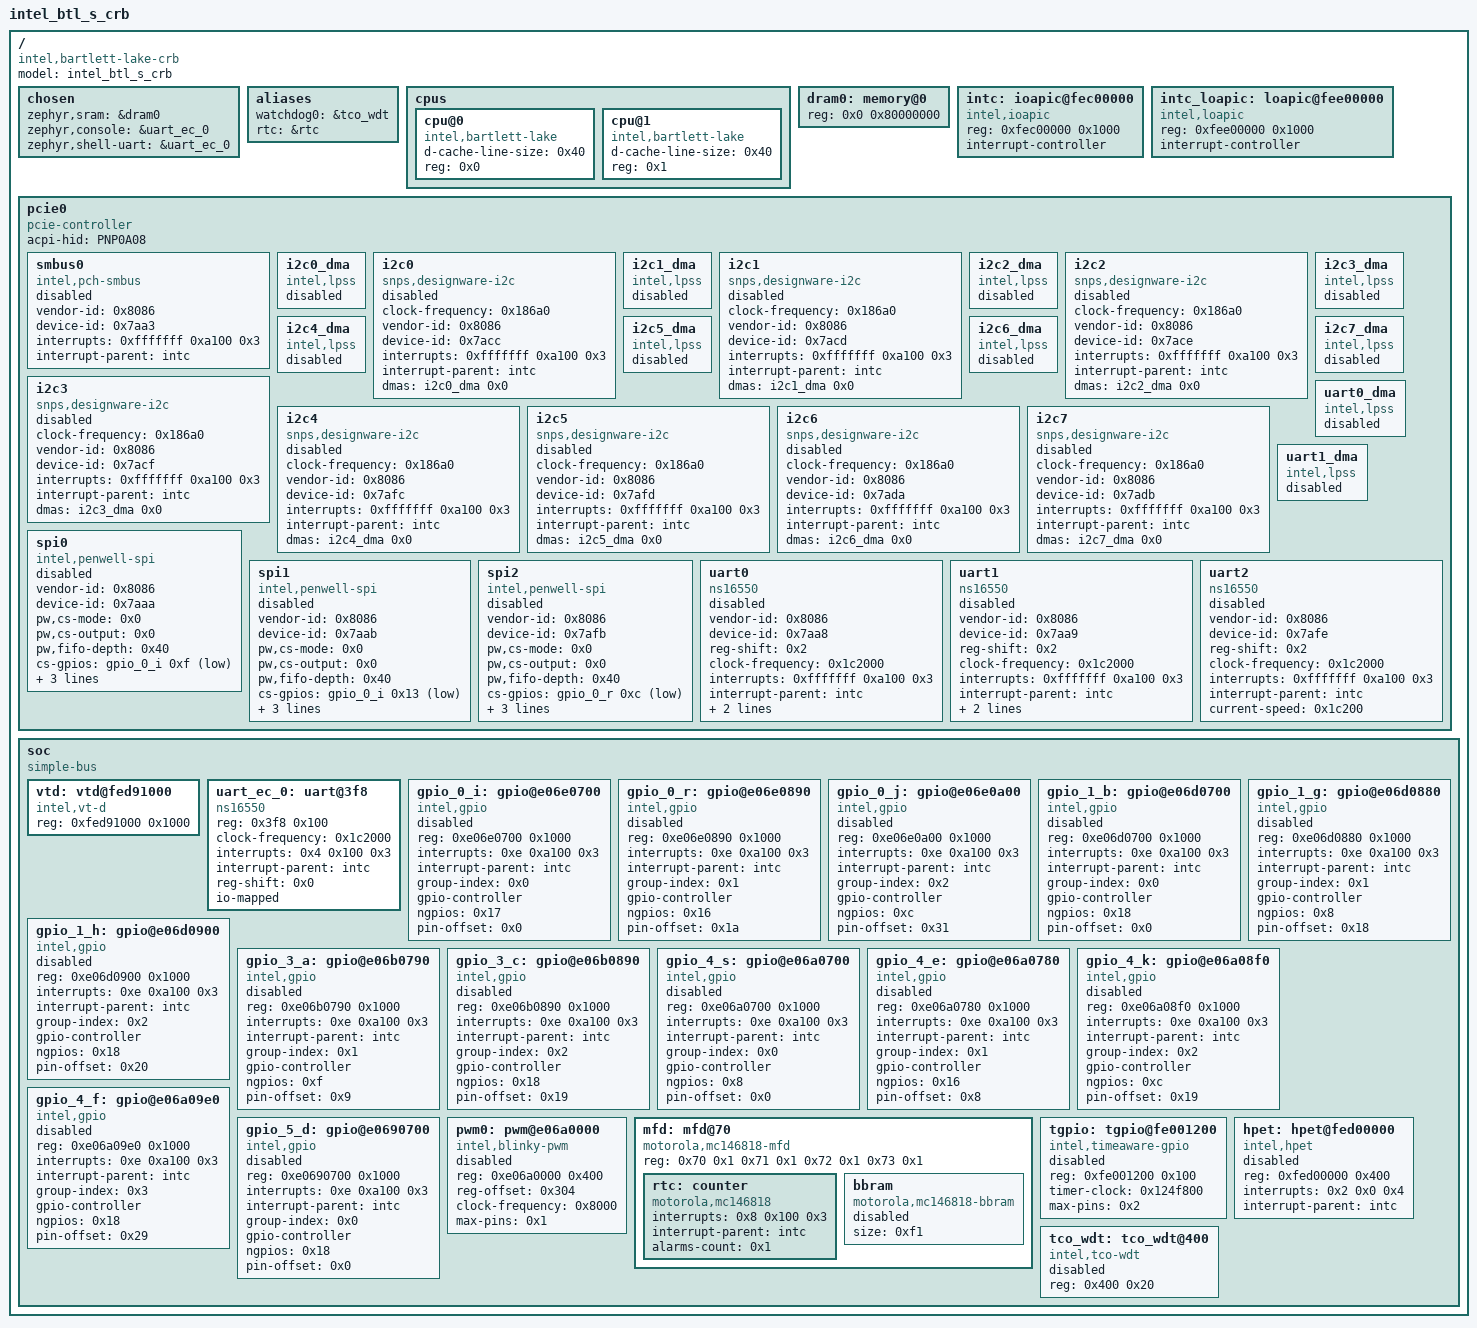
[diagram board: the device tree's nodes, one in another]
/dts-v1/;

/* node '/' defined in zephyr/dts/common/skeleton.dtsi:9 */
/ {
	#address-cells = < 0x1 >;               /* in zephyr/dts/common/skeleton.dtsi:10 */
	#size-cells = < 0x1 >;                  /* in zephyr/dts/common/skeleton.dtsi:11 */
	model = "intel_btl_s_crb";              /* in zephyr/boards/intel/btl/intel_btl_s_crb.dts:15 */
	compatible = "intel,bartlett-lake-crb"; /* in zephyr/boards/intel/btl/intel_btl_s_crb.dts:16 */

	/* node '/chosen' defined in zephyr/dts/common/skeleton.dtsi:13 */
	chosen {
		zephyr,sram = &dram0;           /* in zephyr/boards/intel/btl/intel_btl_s_crb.dts:19 */
		zephyr,console = &uart_ec_0;    /* in zephyr/boards/intel/btl/intel_btl_s_crb.dts:20 */
		zephyr,shell-uart = &uart_ec_0; /* in zephyr/boards/intel/btl/intel_btl_s_crb.dts:21 */
	};

	/* node '/aliases' defined in zephyr/dts/common/skeleton.dtsi:15 */
	aliases {
		watchdog0 = &tco_wdt; /* in zephyr/boards/intel/btl/intel_btl_s_crb.dts:25 */
		rtc = &rtc;           /* in zephyr/boards/intel/btl/intel_btl_s_crb.dts:26 */
	};

	/* node '/cpus' defined in zephyr/dts/x86/intel/bartlett_lake_s.dtsi:13 */
	cpus {
		#address-cells = < 0x1 >; /* in zephyr/dts/x86/intel/bartlett_lake_s.dtsi:14 */
		#size-cells = < 0x0 >;    /* in zephyr/dts/x86/intel/bartlett_lake_s.dtsi:15 */

		/* node '/cpus/cpu@0' defined in zephyr/dts/x86/intel/bartlett_lake_s.dtsi:17 */
		cpu@0 {
			device_type = "cpu";                /* in zephyr/dts/x86/intel/bartlett_lake_s.dtsi:18 */
			compatible = "intel,bartlett-lake"; /* in zephyr/dts/x86/intel/bartlett_lake_s.dtsi:19 */
			d-cache-line-size = < 0x40 >;       /* in zephyr/dts/x86/intel/bartlett_lake_s.dtsi:20 */
			reg = < 0x0 >;                      /* in zephyr/dts/x86/intel/bartlett_lake_s.dtsi:21 */
		};

		/* node '/cpus/cpu@1' defined in zephyr/dts/x86/intel/bartlett_lake_s.dtsi:24 */
		cpu@1 {
			device_type = "cpu";                /* in zephyr/dts/x86/intel/bartlett_lake_s.dtsi:25 */
			compatible = "intel,bartlett-lake"; /* in zephyr/dts/x86/intel/bartlett_lake_s.dtsi:26 */
			d-cache-line-size = < 0x40 >;       /* in zephyr/dts/x86/intel/bartlett_lake_s.dtsi:27 */
			reg = < 0x1 >;                      /* in zephyr/dts/x86/intel/bartlett_lake_s.dtsi:28 */
		};
	};

	/* node '/memory@0' defined in zephyr/dts/x86/intel/bartlett_lake_s.dtsi:32 */
	dram0: memory@0 {
		device_type = "memory";   /* in zephyr/dts/x86/intel/bartlett_lake_s.dtsi:33 */
		reg = < 0x0 0x80000000 >; /* in zephyr/dts/x86/intel/bartlett_lake_s.dtsi:34 */
	};

	/* node '/ioapic@fec00000' defined in zephyr/dts/x86/intel/bartlett_lake_s.dtsi:37 */
	intc: ioapic@fec00000 {
		compatible = "intel,ioapic"; /* in zephyr/dts/x86/intel/bartlett_lake_s.dtsi:38 */
		#address-cells = < 0x1 >;    /* in zephyr/dts/x86/intel/bartlett_lake_s.dtsi:39 */
		#interrupt-cells = < 0x3 >;  /* in zephyr/dts/x86/intel/bartlett_lake_s.dtsi:40 */
		reg = < 0xfec00000 0x1000 >; /* in zephyr/dts/x86/intel/bartlett_lake_s.dtsi:41 */
		interrupt-controller;        /* in zephyr/dts/x86/intel/bartlett_lake_s.dtsi:42 */
		phandle = < 0x1 >;           /* in zephyr/dts/x86/intel/bartlett_lake_s.dtsi:67 */
	};

	/* node '/loapic@fee00000' defined in zephyr/dts/x86/intel/bartlett_lake_s.dtsi:45 */
	intc_loapic: loapic@fee00000 {
		compatible = "intel,loapic"; /* in zephyr/dts/x86/intel/bartlett_lake_s.dtsi:46 */
		reg = < 0xfee00000 0x1000 >; /* in zephyr/dts/x86/intel/bartlett_lake_s.dtsi:47 */
		interrupt-controller;        /* in zephyr/dts/x86/intel/bartlett_lake_s.dtsi:48 */
		#interrupt-cells = < 0x3 >;  /* in zephyr/dts/x86/intel/bartlett_lake_s.dtsi:49 */
		#address-cells = < 0x1 >;    /* in zephyr/dts/x86/intel/bartlett_lake_s.dtsi:50 */
	};

	/* node '/pcie0' defined in zephyr/dts/x86/intel/bartlett_lake_s.dtsi:53 */
	pcie0: pcie0 {
		#address-cells = < 0x1 >;       /* in zephyr/dts/x86/intel/bartlett_lake_s.dtsi:54 */
		#size-cells = < 0x1 >;          /* in zephyr/dts/x86/intel/bartlett_lake_s.dtsi:55 */
		compatible = "pcie-controller"; /* in zephyr/dts/x86/intel/bartlett_lake_s.dtsi:56 */
		acpi-hid = "PNP0A08";           /* in zephyr/dts/x86/intel/bartlett_lake_s.dtsi:57 */
		ranges;                         /* in zephyr/dts/x86/intel/bartlett_lake_s.dtsi:58 */

		/* node '/pcie0/smbus0' defined in zephyr/dts/x86/intel/bartlett_lake_s.dtsi:60 */
		smbus0: smbus0 {
			compatible = "intel,pch-smbus";        /* in zephyr/dts/x86/intel/bartlett_lake_s.dtsi:61 */
			#address-cells = < 0x1 >;              /* in zephyr/dts/x86/intel/bartlett_lake_s.dtsi:62 */
			#size-cells = < 0x0 >;                 /* in zephyr/dts/x86/intel/bartlett_lake_s.dtsi:63 */
			vendor-id = < 0x8086 >;                /* in zephyr/dts/x86/intel/bartlett_lake_s.dtsi:64 */
			device-id = < 0x7aa3 >;                /* in zephyr/dts/x86/intel/bartlett_lake_s.dtsi:65 */
			interrupts = < 0xfffffff 0xa100 0x3 >; /* in zephyr/dts/x86/intel/bartlett_lake_s.dtsi:66 */
			interrupt-parent = < &intc >;          /* in zephyr/dts/x86/intel/bartlett_lake_s.dtsi:67 */
			status = "disabled";                   /* in zephyr/dts/x86/intel/bartlett_lake_s.dtsi:69 */
		};

		/* node '/pcie0/i2c0_dma' defined in zephyr/dts/x86/intel/bartlett_lake_s.dtsi:72 */
		i2c0_dma: i2c0_dma {
			compatible = "intel,lpss"; /* in zephyr/dts/x86/intel/bartlett_lake_s.dtsi:73 */
			#dma-cells = < 0x1 >;      /* in zephyr/dts/x86/intel/bartlett_lake_s.dtsi:74 */
			status = "disabled";       /* in zephyr/dts/x86/intel/bartlett_lake_s.dtsi:76 */
			phandle = < 0x2 >;         /* in zephyr/dts/x86/intel/bartlett_lake_s.dtsi:88 */
		};

		/* node '/pcie0/i2c0' defined in zephyr/dts/x86/intel/bartlett_lake_s.dtsi:79 */
		i2c0: i2c0 {
			compatible = "snps,designware-i2c";    /* in zephyr/dts/x86/intel/bartlett_lake_s.dtsi:80 */
			clock-frequency = < 0x186a0 >;         /* in zephyr/dts/x86/intel/bartlett_lake_s.dtsi:81 */
			#address-cells = < 0x1 >;              /* in zephyr/dts/x86/intel/bartlett_lake_s.dtsi:82 */
			#size-cells = < 0x0 >;                 /* in zephyr/dts/x86/intel/bartlett_lake_s.dtsi:83 */
			vendor-id = < 0x8086 >;                /* in zephyr/dts/x86/intel/bartlett_lake_s.dtsi:84 */
			device-id = < 0x7acc >;                /* in zephyr/dts/x86/intel/bartlett_lake_s.dtsi:85 */
			interrupts = < 0xfffffff 0xa100 0x3 >; /* in zephyr/dts/x86/intel/bartlett_lake_s.dtsi:86 */
			interrupt-parent = < &intc >;          /* in zephyr/dts/x86/intel/bartlett_lake_s.dtsi:87 */
			dmas = < &i2c0_dma 0x0 >;              /* in zephyr/dts/x86/intel/bartlett_lake_s.dtsi:88 */
			status = "disabled";                   /* in zephyr/dts/x86/intel/bartlett_lake_s.dtsi:90 */
		};

		/* node '/pcie0/i2c1_dma' defined in zephyr/dts/x86/intel/bartlett_lake_s.dtsi:93 */
		i2c1_dma: i2c1_dma {
			compatible = "intel,lpss"; /* in zephyr/dts/x86/intel/bartlett_lake_s.dtsi:94 */
			#dma-cells = < 0x1 >;      /* in zephyr/dts/x86/intel/bartlett_lake_s.dtsi:95 */
			status = "disabled";       /* in zephyr/dts/x86/intel/bartlett_lake_s.dtsi:97 */
			phandle = < 0x3 >;         /* in zephyr/dts/x86/intel/bartlett_lake_s.dtsi:109 */
		};

		/* node '/pcie0/i2c1' defined in zephyr/dts/x86/intel/bartlett_lake_s.dtsi:100 */
		i2c1: i2c1 {
			compatible = "snps,designware-i2c";    /* in zephyr/dts/x86/intel/bartlett_lake_s.dtsi:101 */
			clock-frequency = < 0x186a0 >;         /* in zephyr/dts/x86/intel/bartlett_lake_s.dtsi:102 */
			#address-cells = < 0x1 >;              /* in zephyr/dts/x86/intel/bartlett_lake_s.dtsi:103 */
			#size-cells = < 0x0 >;                 /* in zephyr/dts/x86/intel/bartlett_lake_s.dtsi:104 */
			vendor-id = < 0x8086 >;                /* in zephyr/dts/x86/intel/bartlett_lake_s.dtsi:105 */
			device-id = < 0x7acd >;                /* in zephyr/dts/x86/intel/bartlett_lake_s.dtsi:106 */
			interrupts = < 0xfffffff 0xa100 0x3 >; /* in zephyr/dts/x86/intel/bartlett_lake_s.dtsi:107 */
			interrupt-parent = < &intc >;          /* in zephyr/dts/x86/intel/bartlett_lake_s.dtsi:108 */
			dmas = < &i2c1_dma 0x0 >;              /* in zephyr/dts/x86/intel/bartlett_lake_s.dtsi:109 */
			status = "disabled";                   /* in zephyr/dts/x86/intel/bartlett_lake_s.dtsi:111 */
		};

		/* node '/pcie0/i2c2_dma' defined in zephyr/dts/x86/intel/bartlett_lake_s.dtsi:114 */
		i2c2_dma: i2c2_dma {
			compatible = "intel,lpss"; /* in zephyr/dts/x86/intel/bartlett_lake_s.dtsi:115 */
			#dma-cells = < 0x1 >;      /* in zephyr/dts/x86/intel/bartlett_lake_s.dtsi:116 */
			status = "disabled";       /* in zephyr/dts/x86/intel/bartlett_lake_s.dtsi:118 */
			phandle = < 0x4 >;         /* in zephyr/dts/x86/intel/bartlett_lake_s.dtsi:132 */
		};

		/* node '/pcie0/i2c2' defined in zephyr/dts/x86/intel/bartlett_lake_s.dtsi:121 */
		i2c2: i2c2 {
			compatible = "snps,designware-i2c";    /* in zephyr/dts/x86/intel/bartlett_lake_s.dtsi:122 */
			clock-frequency = < 0x186a0 >;         /* in zephyr/dts/x86/intel/bartlett_lake_s.dtsi:123 */
			#address-cells = < 0x1 >;              /* in zephyr/dts/x86/intel/bartlett_lake_s.dtsi:126 */
			#size-cells = < 0x0 >;                 /* in zephyr/dts/x86/intel/bartlett_lake_s.dtsi:127 */
			vendor-id = < 0x8086 >;                /* in zephyr/dts/x86/intel/bartlett_lake_s.dtsi:128 */
			device-id = < 0x7ace >;                /* in zephyr/dts/x86/intel/bartlett_lake_s.dtsi:129 */
			interrupts = < 0xfffffff 0xa100 0x3 >; /* in zephyr/dts/x86/intel/bartlett_lake_s.dtsi:130 */
			interrupt-parent = < &intc >;          /* in zephyr/dts/x86/intel/bartlett_lake_s.dtsi:131 */
			dmas = < &i2c2_dma 0x0 >;              /* in zephyr/dts/x86/intel/bartlett_lake_s.dtsi:132 */
			status = "disabled";                   /* in zephyr/dts/x86/intel/bartlett_lake_s.dtsi:134 */
		};

		/* node '/pcie0/i2c3_dma' defined in zephyr/dts/x86/intel/bartlett_lake_s.dtsi:137 */
		i2c3_dma: i2c3_dma {
			compatible = "intel,lpss"; /* in zephyr/dts/x86/intel/bartlett_lake_s.dtsi:138 */
			#dma-cells = < 0x1 >;      /* in zephyr/dts/x86/intel/bartlett_lake_s.dtsi:139 */
			status = "disabled";       /* in zephyr/dts/x86/intel/bartlett_lake_s.dtsi:141 */
			phandle = < 0x5 >;         /* in zephyr/dts/x86/intel/bartlett_lake_s.dtsi:153 */
		};

		/* node '/pcie0/i2c3' defined in zephyr/dts/x86/intel/bartlett_lake_s.dtsi:144 */
		i2c3: i2c3 {
			compatible = "snps,designware-i2c";    /* in zephyr/dts/x86/intel/bartlett_lake_s.dtsi:145 */
			clock-frequency = < 0x186a0 >;         /* in zephyr/dts/x86/intel/bartlett_lake_s.dtsi:146 */
			#address-cells = < 0x1 >;              /* in zephyr/dts/x86/intel/bartlett_lake_s.dtsi:147 */
			#size-cells = < 0x0 >;                 /* in zephyr/dts/x86/intel/bartlett_lake_s.dtsi:148 */
			vendor-id = < 0x8086 >;                /* in zephyr/dts/x86/intel/bartlett_lake_s.dtsi:149 */
			device-id = < 0x7acf >;                /* in zephyr/dts/x86/intel/bartlett_lake_s.dtsi:150 */
			interrupts = < 0xfffffff 0xa100 0x3 >; /* in zephyr/dts/x86/intel/bartlett_lake_s.dtsi:151 */
			interrupt-parent = < &intc >;          /* in zephyr/dts/x86/intel/bartlett_lake_s.dtsi:152 */
			dmas = < &i2c3_dma 0x0 >;              /* in zephyr/dts/x86/intel/bartlett_lake_s.dtsi:153 */
			status = "disabled";                   /* in zephyr/dts/x86/intel/bartlett_lake_s.dtsi:155 */
		};

		/* node '/pcie0/i2c4_dma' defined in zephyr/dts/x86/intel/bartlett_lake_s.dtsi:158 */
		i2c4_dma: i2c4_dma {
			compatible = "intel,lpss"; /* in zephyr/dts/x86/intel/bartlett_lake_s.dtsi:159 */
			#dma-cells = < 0x1 >;      /* in zephyr/dts/x86/intel/bartlett_lake_s.dtsi:160 */
			status = "disabled";       /* in zephyr/dts/x86/intel/bartlett_lake_s.dtsi:162 */
			phandle = < 0x6 >;         /* in zephyr/dts/x86/intel/bartlett_lake_s.dtsi:174 */
		};

		/* node '/pcie0/i2c4' defined in zephyr/dts/x86/intel/bartlett_lake_s.dtsi:165 */
		i2c4: i2c4 {
			compatible = "snps,designware-i2c";    /* in zephyr/dts/x86/intel/bartlett_lake_s.dtsi:166 */
			clock-frequency = < 0x186a0 >;         /* in zephyr/dts/x86/intel/bartlett_lake_s.dtsi:167 */
			#address-cells = < 0x1 >;              /* in zephyr/dts/x86/intel/bartlett_lake_s.dtsi:168 */
			#size-cells = < 0x0 >;                 /* in zephyr/dts/x86/intel/bartlett_lake_s.dtsi:169 */
			vendor-id = < 0x8086 >;                /* in zephyr/dts/x86/intel/bartlett_lake_s.dtsi:170 */
			device-id = < 0x7afc >;                /* in zephyr/dts/x86/intel/bartlett_lake_s.dtsi:171 */
			interrupts = < 0xfffffff 0xa100 0x3 >; /* in zephyr/dts/x86/intel/bartlett_lake_s.dtsi:172 */
			interrupt-parent = < &intc >;          /* in zephyr/dts/x86/intel/bartlett_lake_s.dtsi:173 */
			dmas = < &i2c4_dma 0x0 >;              /* in zephyr/dts/x86/intel/bartlett_lake_s.dtsi:174 */
			status = "disabled";                   /* in zephyr/dts/x86/intel/bartlett_lake_s.dtsi:176 */
		};

		/* node '/pcie0/i2c5_dma' defined in zephyr/dts/x86/intel/bartlett_lake_s.dtsi:179 */
		i2c5_dma: i2c5_dma {
			compatible = "intel,lpss"; /* in zephyr/dts/x86/intel/bartlett_lake_s.dtsi:180 */
			#dma-cells = < 0x1 >;      /* in zephyr/dts/x86/intel/bartlett_lake_s.dtsi:181 */
			status = "disabled";       /* in zephyr/dts/x86/intel/bartlett_lake_s.dtsi:183 */
			phandle = < 0x7 >;         /* in zephyr/dts/x86/intel/bartlett_lake_s.dtsi:195 */
		};

		/* node '/pcie0/i2c5' defined in zephyr/dts/x86/intel/bartlett_lake_s.dtsi:186 */
		i2c5: i2c5 {
			compatible = "snps,designware-i2c";    /* in zephyr/dts/x86/intel/bartlett_lake_s.dtsi:187 */
			clock-frequency = < 0x186a0 >;         /* in zephyr/dts/x86/intel/bartlett_lake_s.dtsi:188 */
			#address-cells = < 0x1 >;              /* in zephyr/dts/x86/intel/bartlett_lake_s.dtsi:189 */
			#size-cells = < 0x0 >;                 /* in zephyr/dts/x86/intel/bartlett_lake_s.dtsi:190 */
			vendor-id = < 0x8086 >;                /* in zephyr/dts/x86/intel/bartlett_lake_s.dtsi:191 */
			device-id = < 0x7afd >;                /* in zephyr/dts/x86/intel/bartlett_lake_s.dtsi:192 */
			interrupts = < 0xfffffff 0xa100 0x3 >; /* in zephyr/dts/x86/intel/bartlett_lake_s.dtsi:193 */
			interrupt-parent = < &intc >;          /* in zephyr/dts/x86/intel/bartlett_lake_s.dtsi:194 */
			dmas = < &i2c5_dma 0x0 >;              /* in zephyr/dts/x86/intel/bartlett_lake_s.dtsi:195 */
			status = "disabled";                   /* in zephyr/dts/x86/intel/bartlett_lake_s.dtsi:197 */
		};

		/* node '/pcie0/i2c6_dma' defined in zephyr/dts/x86/intel/bartlett_lake_s.dtsi:200 */
		i2c6_dma: i2c6_dma {
			compatible = "intel,lpss"; /* in zephyr/dts/x86/intel/bartlett_lake_s.dtsi:201 */
			#dma-cells = < 0x1 >;      /* in zephyr/dts/x86/intel/bartlett_lake_s.dtsi:202 */
			status = "disabled";       /* in zephyr/dts/x86/intel/bartlett_lake_s.dtsi:204 */
			phandle = < 0x8 >;         /* in zephyr/dts/x86/intel/bartlett_lake_s.dtsi:216 */
		};

		/* node '/pcie0/i2c6' defined in zephyr/dts/x86/intel/bartlett_lake_s.dtsi:207 */
		i2c6: i2c6 {
			compatible = "snps,designware-i2c";    /* in zephyr/dts/x86/intel/bartlett_lake_s.dtsi:208 */
			clock-frequency = < 0x186a0 >;         /* in zephyr/dts/x86/intel/bartlett_lake_s.dtsi:209 */
			#address-cells = < 0x1 >;              /* in zephyr/dts/x86/intel/bartlett_lake_s.dtsi:210 */
			#size-cells = < 0x0 >;                 /* in zephyr/dts/x86/intel/bartlett_lake_s.dtsi:211 */
			vendor-id = < 0x8086 >;                /* in zephyr/dts/x86/intel/bartlett_lake_s.dtsi:212 */
			device-id = < 0x7ada >;                /* in zephyr/dts/x86/intel/bartlett_lake_s.dtsi:213 */
			interrupts = < 0xfffffff 0xa100 0x3 >; /* in zephyr/dts/x86/intel/bartlett_lake_s.dtsi:214 */
			interrupt-parent = < &intc >;          /* in zephyr/dts/x86/intel/bartlett_lake_s.dtsi:215 */
			dmas = < &i2c6_dma 0x0 >;              /* in zephyr/dts/x86/intel/bartlett_lake_s.dtsi:216 */
			status = "disabled";                   /* in zephyr/dts/x86/intel/bartlett_lake_s.dtsi:218 */
		};

		/* node '/pcie0/i2c7_dma' defined in zephyr/dts/x86/intel/bartlett_lake_s.dtsi:221 */
		i2c7_dma: i2c7_dma {
			compatible = "intel,lpss"; /* in zephyr/dts/x86/intel/bartlett_lake_s.dtsi:222 */
			#dma-cells = < 0x1 >;      /* in zephyr/dts/x86/intel/bartlett_lake_s.dtsi:223 */
			status = "disabled";       /* in zephyr/dts/x86/intel/bartlett_lake_s.dtsi:225 */
			phandle = < 0x9 >;         /* in zephyr/dts/x86/intel/bartlett_lake_s.dtsi:237 */
		};

		/* node '/pcie0/i2c7' defined in zephyr/dts/x86/intel/bartlett_lake_s.dtsi:228 */
		i2c7: i2c7 {
			compatible = "snps,designware-i2c";    /* in zephyr/dts/x86/intel/bartlett_lake_s.dtsi:229 */
			clock-frequency = < 0x186a0 >;         /* in zephyr/dts/x86/intel/bartlett_lake_s.dtsi:230 */
			#address-cells = < 0x1 >;              /* in zephyr/dts/x86/intel/bartlett_lake_s.dtsi:231 */
			#size-cells = < 0x0 >;                 /* in zephyr/dts/x86/intel/bartlett_lake_s.dtsi:232 */
			vendor-id = < 0x8086 >;                /* in zephyr/dts/x86/intel/bartlett_lake_s.dtsi:233 */
			device-id = < 0x7adb >;                /* in zephyr/dts/x86/intel/bartlett_lake_s.dtsi:234 */
			interrupts = < 0xfffffff 0xa100 0x3 >; /* in zephyr/dts/x86/intel/bartlett_lake_s.dtsi:235 */
			interrupt-parent = < &intc >;          /* in zephyr/dts/x86/intel/bartlett_lake_s.dtsi:236 */
			dmas = < &i2c7_dma 0x0 >;              /* in zephyr/dts/x86/intel/bartlett_lake_s.dtsi:237 */
			status = "disabled";                   /* in zephyr/dts/x86/intel/bartlett_lake_s.dtsi:239 */
		};

		/* node '/pcie0/spi0' defined in zephyr/dts/x86/intel/bartlett_lake_s.dtsi:242 */
		spi0: spi0 {
			compatible = "intel,penwell-spi";      /* in zephyr/dts/x86/intel/bartlett_lake_s.dtsi:243 */
			vendor-id = < 0x8086 >;                /* in zephyr/dts/x86/intel/bartlett_lake_s.dtsi:244 */
			device-id = < 0x7aaa >;                /* in zephyr/dts/x86/intel/bartlett_lake_s.dtsi:245 */
			#address-cells = < 0x1 >;              /* in zephyr/dts/x86/intel/bartlett_lake_s.dtsi:246 */
			#size-cells = < 0x0 >;                 /* in zephyr/dts/x86/intel/bartlett_lake_s.dtsi:247 */
			pw,cs-mode = < 0x0 >;                  /* in zephyr/dts/x86/intel/bartlett_lake_s.dtsi:248 */
			pw,cs-output = < 0x0 >;                /* in zephyr/dts/x86/intel/bartlett_lake_s.dtsi:249 */
			pw,fifo-depth = < 0x40 >;              /* in zephyr/dts/x86/intel/bartlett_lake_s.dtsi:250 */
			cs-gpios = < &gpio_0_i 0xf 0x1 >;      /* in zephyr/dts/x86/intel/bartlett_lake_s.dtsi:251 */
			clock-frequency = < 0x5f5e100 >;       /* in zephyr/dts/x86/intel/bartlett_lake_s.dtsi:252 */
			interrupts = < 0xfffffff 0xa100 0x3 >; /* in zephyr/dts/x86/intel/bartlett_lake_s.dtsi:253 */
			interrupt-parent = < &intc >;          /* in zephyr/dts/x86/intel/bartlett_lake_s.dtsi:254 */
			status = "disabled";                   /* in zephyr/dts/x86/intel/bartlett_lake_s.dtsi:256 */
		};

		/* node '/pcie0/spi1' defined in zephyr/dts/x86/intel/bartlett_lake_s.dtsi:259 */
		spi1: spi1 {
			compatible = "intel,penwell-spi";      /* in zephyr/dts/x86/intel/bartlett_lake_s.dtsi:260 */
			vendor-id = < 0x8086 >;                /* in zephyr/dts/x86/intel/bartlett_lake_s.dtsi:261 */
			device-id = < 0x7aab >;                /* in zephyr/dts/x86/intel/bartlett_lake_s.dtsi:262 */
			#address-cells = < 0x1 >;              /* in zephyr/dts/x86/intel/bartlett_lake_s.dtsi:263 */
			#size-cells = < 0x0 >;                 /* in zephyr/dts/x86/intel/bartlett_lake_s.dtsi:264 */
			pw,cs-mode = < 0x0 >;                  /* in zephyr/dts/x86/intel/bartlett_lake_s.dtsi:265 */
			pw,cs-output = < 0x0 >;                /* in zephyr/dts/x86/intel/bartlett_lake_s.dtsi:266 */
			pw,fifo-depth = < 0x40 >;              /* in zephyr/dts/x86/intel/bartlett_lake_s.dtsi:267 */
			cs-gpios = < &gpio_0_i 0x13 0x1 >;     /* in zephyr/dts/x86/intel/bartlett_lake_s.dtsi:268 */
			clock-frequency = < 0x5f5e100 >;       /* in zephyr/dts/x86/intel/bartlett_lake_s.dtsi:269 */
			interrupts = < 0xfffffff 0xa100 0x3 >; /* in zephyr/dts/x86/intel/bartlett_lake_s.dtsi:270 */
			interrupt-parent = < &intc >;          /* in zephyr/dts/x86/intel/bartlett_lake_s.dtsi:271 */
			status = "disabled";                   /* in zephyr/dts/x86/intel/bartlett_lake_s.dtsi:273 */
		};

		/* node '/pcie0/spi2' defined in zephyr/dts/x86/intel/bartlett_lake_s.dtsi:276 */
		spi2: spi2 {
			compatible = "intel,penwell-spi";      /* in zephyr/dts/x86/intel/bartlett_lake_s.dtsi:277 */
			vendor-id = < 0x8086 >;                /* in zephyr/dts/x86/intel/bartlett_lake_s.dtsi:278 */
			device-id = < 0x7afb >;                /* in zephyr/dts/x86/intel/bartlett_lake_s.dtsi:279 */
			#address-cells = < 0x1 >;              /* in zephyr/dts/x86/intel/bartlett_lake_s.dtsi:280 */
			#size-cells = < 0x0 >;                 /* in zephyr/dts/x86/intel/bartlett_lake_s.dtsi:281 */
			pw,cs-mode = < 0x0 >;                  /* in zephyr/dts/x86/intel/bartlett_lake_s.dtsi:282 */
			pw,cs-output = < 0x0 >;                /* in zephyr/dts/x86/intel/bartlett_lake_s.dtsi:283 */
			pw,fifo-depth = < 0x40 >;              /* in zephyr/dts/x86/intel/bartlett_lake_s.dtsi:284 */
			cs-gpios = < &gpio_0_r 0xc 0x1 >;      /* in zephyr/dts/x86/intel/bartlett_lake_s.dtsi:285 */
			clock-frequency = < 0x5f5e100 >;       /* in zephyr/dts/x86/intel/bartlett_lake_s.dtsi:286 */
			interrupts = < 0xfffffff 0xa100 0x3 >; /* in zephyr/dts/x86/intel/bartlett_lake_s.dtsi:287 */
			interrupt-parent = < &intc >;          /* in zephyr/dts/x86/intel/bartlett_lake_s.dtsi:288 */
			status = "disabled";                   /* in zephyr/dts/x86/intel/bartlett_lake_s.dtsi:290 */
		};

		/* node '/pcie0/uart0_dma' defined in zephyr/dts/x86/intel/bartlett_lake_s.dtsi:293 */
		uart0_dma: uart0_dma {
			compatible = "intel,lpss"; /* in zephyr/dts/x86/intel/bartlett_lake_s.dtsi:294 */
			#dma-cells = < 0x1 >;      /* in zephyr/dts/x86/intel/bartlett_lake_s.dtsi:295 */
			status = "disabled";       /* in zephyr/dts/x86/intel/bartlett_lake_s.dtsi:297 */
			phandle = < 0xc >;         /* in zephyr/dts/x86/intel/bartlett_lake_s.dtsi:309 */
		};

		/* node '/pcie0/uart0' defined in zephyr/dts/x86/intel/bartlett_lake_s.dtsi:300 */
		uart0: uart0 {
			compatible = "ns16550";                /* in zephyr/dts/x86/intel/bartlett_lake_s.dtsi:301 */
			vendor-id = < 0x8086 >;                /* in zephyr/dts/x86/intel/bartlett_lake_s.dtsi:302 */
			device-id = < 0x7aa8 >;                /* in zephyr/dts/x86/intel/bartlett_lake_s.dtsi:303 */
			reg-shift = < 0x2 >;                   /* in zephyr/dts/x86/intel/bartlett_lake_s.dtsi:304 */
			clock-frequency = < 0x1c2000 >;        /* in zephyr/dts/x86/intel/bartlett_lake_s.dtsi:305 */
			interrupts = < 0xfffffff 0xa100 0x3 >; /* in zephyr/dts/x86/intel/bartlett_lake_s.dtsi:306 */
			interrupt-parent = < &intc >;          /* in zephyr/dts/x86/intel/bartlett_lake_s.dtsi:307 */
			current-speed = < 0x1c200 >;           /* in zephyr/dts/x86/intel/bartlett_lake_s.dtsi:308 */
			dmas = < &uart0_dma 0x0 >,
			       < &uart0_dma 0x1 >;             /* in zephyr/dts/x86/intel/bartlett_lake_s.dtsi:309 */
			dma-names = "tx",
			            "rx";                      /* in zephyr/dts/x86/intel/bartlett_lake_s.dtsi:310 */
			status = "disabled";                   /* in zephyr/dts/x86/intel/bartlett_lake_s.dtsi:312 */
		};

		/* node '/pcie0/uart1_dma' defined in zephyr/dts/x86/intel/bartlett_lake_s.dtsi:315 */
		uart1_dma: uart1_dma {
			compatible = "intel,lpss"; /* in zephyr/dts/x86/intel/bartlett_lake_s.dtsi:316 */
			#dma-cells = < 0x1 >;      /* in zephyr/dts/x86/intel/bartlett_lake_s.dtsi:317 */
			status = "disabled";       /* in zephyr/dts/x86/intel/bartlett_lake_s.dtsi:319 */
			phandle = < 0xd >;         /* in zephyr/dts/x86/intel/bartlett_lake_s.dtsi:331 */
		};

		/* node '/pcie0/uart1' defined in zephyr/dts/x86/intel/bartlett_lake_s.dtsi:322 */
		uart1: uart1 {
			compatible = "ns16550";                /* in zephyr/dts/x86/intel/bartlett_lake_s.dtsi:323 */
			vendor-id = < 0x8086 >;                /* in zephyr/dts/x86/intel/bartlett_lake_s.dtsi:324 */
			device-id = < 0x7aa9 >;                /* in zephyr/dts/x86/intel/bartlett_lake_s.dtsi:325 */
			reg-shift = < 0x2 >;                   /* in zephyr/dts/x86/intel/bartlett_lake_s.dtsi:326 */
			clock-frequency = < 0x1c2000 >;        /* in zephyr/dts/x86/intel/bartlett_lake_s.dtsi:327 */
			interrupts = < 0xfffffff 0xa100 0x3 >; /* in zephyr/dts/x86/intel/bartlett_lake_s.dtsi:328 */
			interrupt-parent = < &intc >;          /* in zephyr/dts/x86/intel/bartlett_lake_s.dtsi:329 */
			current-speed = < 0x1c200 >;           /* in zephyr/dts/x86/intel/bartlett_lake_s.dtsi:330 */
			dmas = < &uart1_dma 0x0 >,
			       < &uart1_dma 0x1 >;             /* in zephyr/dts/x86/intel/bartlett_lake_s.dtsi:331 */
			dma-names = "tx",
			            "rx";                      /* in zephyr/dts/x86/intel/bartlett_lake_s.dtsi:332 */
			status = "disabled";                   /* in zephyr/dts/x86/intel/bartlett_lake_s.dtsi:334 */
		};

		/* node '/pcie0/uart2' defined in zephyr/dts/x86/intel/bartlett_lake_s.dtsi:337 */
		uart2: uart2 {
			compatible = "ns16550";                /* in zephyr/dts/x86/intel/bartlett_lake_s.dtsi:338 */
			vendor-id = < 0x8086 >;                /* in zephyr/dts/x86/intel/bartlett_lake_s.dtsi:339 */
			device-id = < 0x7afe >;                /* in zephyr/dts/x86/intel/bartlett_lake_s.dtsi:340 */
			reg-shift = < 0x2 >;                   /* in zephyr/dts/x86/intel/bartlett_lake_s.dtsi:341 */
			clock-frequency = < 0x1c2000 >;        /* in zephyr/dts/x86/intel/bartlett_lake_s.dtsi:342 */
			interrupts = < 0xfffffff 0xa100 0x3 >; /* in zephyr/dts/x86/intel/bartlett_lake_s.dtsi:343 */
			interrupt-parent = < &intc >;          /* in zephyr/dts/x86/intel/bartlett_lake_s.dtsi:344 */
			current-speed = < 0x1c200 >;           /* in zephyr/dts/x86/intel/bartlett_lake_s.dtsi:345 */
			status = "disabled";                   /* in zephyr/dts/x86/intel/bartlett_lake_s.dtsi:347 */
		};
	};

	/* node '/soc' defined in zephyr/dts/x86/intel/bartlett_lake_s.dtsi:351 */
	soc {
		#address-cells = < 0x1 >;  /* in zephyr/dts/x86/intel/bartlett_lake_s.dtsi:352 */
		#size-cells = < 0x1 >;     /* in zephyr/dts/x86/intel/bartlett_lake_s.dtsi:353 */
		compatible = "simple-bus"; /* in zephyr/dts/x86/intel/bartlett_lake_s.dtsi:354 */
		ranges;                    /* in zephyr/dts/x86/intel/bartlett_lake_s.dtsi:355 */

		/* node '/soc/vtd@fed91000' defined in zephyr/dts/x86/intel/bartlett_lake_s.dtsi:357 */
		vtd: vtd@fed91000 {
			compatible = "intel,vt-d";   /* in zephyr/dts/x86/intel/bartlett_lake_s.dtsi:358 */
			reg = < 0xfed91000 0x1000 >; /* in zephyr/dts/x86/intel/bartlett_lake_s.dtsi:359 */
			status = "okay";             /* in zephyr/dts/x86/intel/bartlett_lake_s.dtsi:361 */
		};

		/* node '/soc/uart@3f8' defined in zephyr/dts/x86/intel/bartlett_lake_s.dtsi:364 */
		uart_ec_0: uart@3f8 {
			compatible = "ns16550";         /* in zephyr/dts/x86/intel/bartlett_lake_s.dtsi:365 */
			reg = < 0x3f8 0x100 >;          /* in zephyr/dts/x86/intel/bartlett_lake_s.dtsi:366 */
			clock-frequency = < 0x1c2000 >; /* in zephyr/dts/x86/intel/bartlett_lake_s.dtsi:368 */
			interrupts = < 0x4 0x100 0x3 >; /* in zephyr/dts/x86/intel/bartlett_lake_s.dtsi:369 */
			interrupt-parent = < &intc >;   /* in zephyr/dts/x86/intel/bartlett_lake_s.dtsi:370 */
			reg-shift = < 0x0 >;            /* in zephyr/dts/x86/intel/bartlett_lake_s.dtsi:371 */
			io-mapped;                      /* in zephyr/dts/x86/intel/bartlett_lake_s.dtsi:372 */
			status = "okay";                /* in zephyr/boards/intel/btl/intel_btl_s_crb.dts:31 */
		};

		/* node '/soc/gpio@e06e0700' defined in zephyr/dts/x86/intel/bartlett_lake_s.dtsi:377 */
		gpio_0_i: gpio@e06e0700 {
			compatible = "intel,gpio";       /* in zephyr/dts/x86/intel/bartlett_lake_s.dtsi:378 */
			reg = < 0xe06e0700 0x1000 >;     /* in zephyr/dts/x86/intel/bartlett_lake_s.dtsi:379 */
			interrupts = < 0xe 0xa100 0x3 >; /* in zephyr/dts/x86/intel/bartlett_lake_s.dtsi:380 */
			interrupt-parent = < &intc >;    /* in zephyr/dts/x86/intel/bartlett_lake_s.dtsi:381 */
			group-index = < 0x0 >;           /* in zephyr/dts/x86/intel/bartlett_lake_s.dtsi:382 */
			gpio-controller;                 /* in zephyr/dts/x86/intel/bartlett_lake_s.dtsi:383 */
			#gpio-cells = < 0x2 >;           /* in zephyr/dts/x86/intel/bartlett_lake_s.dtsi:384 */
			ngpios = < 0x17 >;               /* in zephyr/dts/x86/intel/bartlett_lake_s.dtsi:385 */
			pin-offset = < 0x0 >;            /* in zephyr/dts/x86/intel/bartlett_lake_s.dtsi:386 */
			status = "disabled";             /* in zephyr/dts/x86/intel/bartlett_lake_s.dtsi:388 */
			phandle = < 0xa >;               /* in zephyr/dts/x86/intel/bartlett_lake_s.dtsi:251 */
		};

		/* node '/soc/gpio@e06e0890' defined in zephyr/dts/x86/intel/bartlett_lake_s.dtsi:391 */
		gpio_0_r: gpio@e06e0890 {
			compatible = "intel,gpio";       /* in zephyr/dts/x86/intel/bartlett_lake_s.dtsi:392 */
			reg = < 0xe06e0890 0x1000 >;     /* in zephyr/dts/x86/intel/bartlett_lake_s.dtsi:393 */
			interrupts = < 0xe 0xa100 0x3 >; /* in zephyr/dts/x86/intel/bartlett_lake_s.dtsi:394 */
			interrupt-parent = < &intc >;    /* in zephyr/dts/x86/intel/bartlett_lake_s.dtsi:395 */
			group-index = < 0x1 >;           /* in zephyr/dts/x86/intel/bartlett_lake_s.dtsi:396 */
			gpio-controller;                 /* in zephyr/dts/x86/intel/bartlett_lake_s.dtsi:397 */
			#gpio-cells = < 0x2 >;           /* in zephyr/dts/x86/intel/bartlett_lake_s.dtsi:398 */
			ngpios = < 0x16 >;               /* in zephyr/dts/x86/intel/bartlett_lake_s.dtsi:399 */
			pin-offset = < 0x1a >;           /* in zephyr/dts/x86/intel/bartlett_lake_s.dtsi:400 */
			status = "disabled";             /* in zephyr/dts/x86/intel/bartlett_lake_s.dtsi:402 */
			phandle = < 0xb >;               /* in zephyr/dts/x86/intel/bartlett_lake_s.dtsi:285 */
		};

		/* node '/soc/gpio@e06e0a00' defined in zephyr/dts/x86/intel/bartlett_lake_s.dtsi:405 */
		gpio_0_j: gpio@e06e0a00 {
			compatible = "intel,gpio";       /* in zephyr/dts/x86/intel/bartlett_lake_s.dtsi:406 */
			reg = < 0xe06e0a00 0x1000 >;     /* in zephyr/dts/x86/intel/bartlett_lake_s.dtsi:407 */
			interrupts = < 0xe 0xa100 0x3 >; /* in zephyr/dts/x86/intel/bartlett_lake_s.dtsi:408 */
			interrupt-parent = < &intc >;    /* in zephyr/dts/x86/intel/bartlett_lake_s.dtsi:409 */
			group-index = < 0x2 >;           /* in zephyr/dts/x86/intel/bartlett_lake_s.dtsi:410 */
			gpio-controller;                 /* in zephyr/dts/x86/intel/bartlett_lake_s.dtsi:411 */
			#gpio-cells = < 0x2 >;           /* in zephyr/dts/x86/intel/bartlett_lake_s.dtsi:412 */
			ngpios = < 0xc >;                /* in zephyr/dts/x86/intel/bartlett_lake_s.dtsi:413 */
			pin-offset = < 0x31 >;           /* in zephyr/dts/x86/intel/bartlett_lake_s.dtsi:414 */
			status = "disabled";             /* in zephyr/dts/x86/intel/bartlett_lake_s.dtsi:416 */
		};

		/* node '/soc/gpio@e06d0700' defined in zephyr/dts/x86/intel/bartlett_lake_s.dtsi:419 */
		gpio_1_b: gpio@e06d0700 {
			compatible = "intel,gpio";       /* in zephyr/dts/x86/intel/bartlett_lake_s.dtsi:420 */
			reg = < 0xe06d0700 0x1000 >;     /* in zephyr/dts/x86/intel/bartlett_lake_s.dtsi:421 */
			interrupts = < 0xe 0xa100 0x3 >; /* in zephyr/dts/x86/intel/bartlett_lake_s.dtsi:422 */
			interrupt-parent = < &intc >;    /* in zephyr/dts/x86/intel/bartlett_lake_s.dtsi:423 */
			group-index = < 0x0 >;           /* in zephyr/dts/x86/intel/bartlett_lake_s.dtsi:424 */
			gpio-controller;                 /* in zephyr/dts/x86/intel/bartlett_lake_s.dtsi:425 */
			#gpio-cells = < 0x2 >;           /* in zephyr/dts/x86/intel/bartlett_lake_s.dtsi:426 */
			ngpios = < 0x18 >;               /* in zephyr/dts/x86/intel/bartlett_lake_s.dtsi:427 */
			pin-offset = < 0x0 >;            /* in zephyr/dts/x86/intel/bartlett_lake_s.dtsi:428 */
			status = "disabled";             /* in zephyr/dts/x86/intel/bartlett_lake_s.dtsi:430 */
		};

		/* node '/soc/gpio@e06d0880' defined in zephyr/dts/x86/intel/bartlett_lake_s.dtsi:433 */
		gpio_1_g: gpio@e06d0880 {
			compatible = "intel,gpio";       /* in zephyr/dts/x86/intel/bartlett_lake_s.dtsi:434 */
			reg = < 0xe06d0880 0x1000 >;     /* in zephyr/dts/x86/intel/bartlett_lake_s.dtsi:435 */
			interrupts = < 0xe 0xa100 0x3 >; /* in zephyr/dts/x86/intel/bartlett_lake_s.dtsi:436 */
			interrupt-parent = < &intc >;    /* in zephyr/dts/x86/intel/bartlett_lake_s.dtsi:437 */
			group-index = < 0x1 >;           /* in zephyr/dts/x86/intel/bartlett_lake_s.dtsi:438 */
			gpio-controller;                 /* in zephyr/dts/x86/intel/bartlett_lake_s.dtsi:439 */
			#gpio-cells = < 0x2 >;           /* in zephyr/dts/x86/intel/bartlett_lake_s.dtsi:440 */
			ngpios = < 0x8 >;                /* in zephyr/dts/x86/intel/bartlett_lake_s.dtsi:441 */
			pin-offset = < 0x18 >;           /* in zephyr/dts/x86/intel/bartlett_lake_s.dtsi:442 */
			status = "disabled";             /* in zephyr/dts/x86/intel/bartlett_lake_s.dtsi:444 */
		};

		/* node '/soc/gpio@e06d0900' defined in zephyr/dts/x86/intel/bartlett_lake_s.dtsi:447 */
		gpio_1_h: gpio@e06d0900 {
			compatible = "intel,gpio";       /* in zephyr/dts/x86/intel/bartlett_lake_s.dtsi:448 */
			reg = < 0xe06d0900 0x1000 >;     /* in zephyr/dts/x86/intel/bartlett_lake_s.dtsi:449 */
			interrupts = < 0xe 0xa100 0x3 >; /* in zephyr/dts/x86/intel/bartlett_lake_s.dtsi:450 */
			interrupt-parent = < &intc >;    /* in zephyr/dts/x86/intel/bartlett_lake_s.dtsi:451 */
			group-index = < 0x2 >;           /* in zephyr/dts/x86/intel/bartlett_lake_s.dtsi:452 */
			gpio-controller;                 /* in zephyr/dts/x86/intel/bartlett_lake_s.dtsi:453 */
			#gpio-cells = < 0x2 >;           /* in zephyr/dts/x86/intel/bartlett_lake_s.dtsi:454 */
			ngpios = < 0x18 >;               /* in zephyr/dts/x86/intel/bartlett_lake_s.dtsi:455 */
			pin-offset = < 0x20 >;           /* in zephyr/dts/x86/intel/bartlett_lake_s.dtsi:456 */
			status = "disabled";             /* in zephyr/dts/x86/intel/bartlett_lake_s.dtsi:458 */
		};

		/* node '/soc/gpio@e06b0790' defined in zephyr/dts/x86/intel/bartlett_lake_s.dtsi:461 */
		gpio_3_a: gpio@e06b0790 {
			compatible = "intel,gpio";       /* in zephyr/dts/x86/intel/bartlett_lake_s.dtsi:462 */
			reg = < 0xe06b0790 0x1000 >;     /* in zephyr/dts/x86/intel/bartlett_lake_s.dtsi:463 */
			interrupts = < 0xe 0xa100 0x3 >; /* in zephyr/dts/x86/intel/bartlett_lake_s.dtsi:464 */
			interrupt-parent = < &intc >;    /* in zephyr/dts/x86/intel/bartlett_lake_s.dtsi:465 */
			group-index = < 0x1 >;           /* in zephyr/dts/x86/intel/bartlett_lake_s.dtsi:466 */
			gpio-controller;                 /* in zephyr/dts/x86/intel/bartlett_lake_s.dtsi:467 */
			#gpio-cells = < 0x2 >;           /* in zephyr/dts/x86/intel/bartlett_lake_s.dtsi:468 */
			ngpios = < 0xf >;                /* in zephyr/dts/x86/intel/bartlett_lake_s.dtsi:469 */
			pin-offset = < 0x9 >;            /* in zephyr/dts/x86/intel/bartlett_lake_s.dtsi:470 */
			status = "disabled";             /* in zephyr/dts/x86/intel/bartlett_lake_s.dtsi:472 */
		};

		/* node '/soc/gpio@e06b0890' defined in zephyr/dts/x86/intel/bartlett_lake_s.dtsi:475 */
		gpio_3_c: gpio@e06b0890 {
			compatible = "intel,gpio";       /* in zephyr/dts/x86/intel/bartlett_lake_s.dtsi:476 */
			reg = < 0xe06b0890 0x1000 >;     /* in zephyr/dts/x86/intel/bartlett_lake_s.dtsi:477 */
			interrupts = < 0xe 0xa100 0x3 >; /* in zephyr/dts/x86/intel/bartlett_lake_s.dtsi:478 */
			interrupt-parent = < &intc >;    /* in zephyr/dts/x86/intel/bartlett_lake_s.dtsi:479 */
			group-index = < 0x2 >;           /* in zephyr/dts/x86/intel/bartlett_lake_s.dtsi:480 */
			gpio-controller;                 /* in zephyr/dts/x86/intel/bartlett_lake_s.dtsi:481 */
			#gpio-cells = < 0x2 >;           /* in zephyr/dts/x86/intel/bartlett_lake_s.dtsi:482 */
			ngpios = < 0x18 >;               /* in zephyr/dts/x86/intel/bartlett_lake_s.dtsi:483 */
			pin-offset = < 0x19 >;           /* in zephyr/dts/x86/intel/bartlett_lake_s.dtsi:484 */
			status = "disabled";             /* in zephyr/dts/x86/intel/bartlett_lake_s.dtsi:486 */
		};

		/* node '/soc/gpio@e06a0700' defined in zephyr/dts/x86/intel/bartlett_lake_s.dtsi:489 */
		gpio_4_s: gpio@e06a0700 {
			compatible = "intel,gpio";       /* in zephyr/dts/x86/intel/bartlett_lake_s.dtsi:490 */
			reg = < 0xe06a0700 0x1000 >;     /* in zephyr/dts/x86/intel/bartlett_lake_s.dtsi:491 */
			interrupts = < 0xe 0xa100 0x3 >; /* in zephyr/dts/x86/intel/bartlett_lake_s.dtsi:492 */
			interrupt-parent = < &intc >;    /* in zephyr/dts/x86/intel/bartlett_lake_s.dtsi:493 */
			group-index = < 0x0 >;           /* in zephyr/dts/x86/intel/bartlett_lake_s.dtsi:494 */
			gpio-controller;                 /* in zephyr/dts/x86/intel/bartlett_lake_s.dtsi:495 */
			#gpio-cells = < 0x2 >;           /* in zephyr/dts/x86/intel/bartlett_lake_s.dtsi:496 */
			ngpios = < 0x8 >;                /* in zephyr/dts/x86/intel/bartlett_lake_s.dtsi:497 */
			pin-offset = < 0x0 >;            /* in zephyr/dts/x86/intel/bartlett_lake_s.dtsi:498 */
			status = "disabled";             /* in zephyr/dts/x86/intel/bartlett_lake_s.dtsi:500 */
		};

		/* node '/soc/gpio@e06a0780' defined in zephyr/dts/x86/intel/bartlett_lake_s.dtsi:503 */
		gpio_4_e: gpio@e06a0780 {
			compatible = "intel,gpio";       /* in zephyr/dts/x86/intel/bartlett_lake_s.dtsi:504 */
			reg = < 0xe06a0780 0x1000 >;     /* in zephyr/dts/x86/intel/bartlett_lake_s.dtsi:505 */
			interrupts = < 0xe 0xa100 0x3 >; /* in zephyr/dts/x86/intel/bartlett_lake_s.dtsi:506 */
			interrupt-parent = < &intc >;    /* in zephyr/dts/x86/intel/bartlett_lake_s.dtsi:507 */
			group-index = < 0x1 >;           /* in zephyr/dts/x86/intel/bartlett_lake_s.dtsi:508 */
			gpio-controller;                 /* in zephyr/dts/x86/intel/bartlett_lake_s.dtsi:509 */
			#gpio-cells = < 0x2 >;           /* in zephyr/dts/x86/intel/bartlett_lake_s.dtsi:510 */
			ngpios = < 0x16 >;               /* in zephyr/dts/x86/intel/bartlett_lake_s.dtsi:511 */
			pin-offset = < 0x8 >;            /* in zephyr/dts/x86/intel/bartlett_lake_s.dtsi:512 */
			status = "disabled";             /* in zephyr/dts/x86/intel/bartlett_lake_s.dtsi:514 */
		};

		/* node '/soc/gpio@e06a08f0' defined in zephyr/dts/x86/intel/bartlett_lake_s.dtsi:517 */
		gpio_4_k: gpio@e06a08f0 {
			compatible = "intel,gpio";       /* in zephyr/dts/x86/intel/bartlett_lake_s.dtsi:518 */
			reg = < 0xe06a08f0 0x1000 >;     /* in zephyr/dts/x86/intel/bartlett_lake_s.dtsi:519 */
			interrupts = < 0xe 0xa100 0x3 >; /* in zephyr/dts/x86/intel/bartlett_lake_s.dtsi:520 */
			interrupt-parent = < &intc >;    /* in zephyr/dts/x86/intel/bartlett_lake_s.dtsi:521 */
			group-index = < 0x2 >;           /* in zephyr/dts/x86/intel/bartlett_lake_s.dtsi:522 */
			gpio-controller;                 /* in zephyr/dts/x86/intel/bartlett_lake_s.dtsi:523 */
			#gpio-cells = < 0x2 >;           /* in zephyr/dts/x86/intel/bartlett_lake_s.dtsi:524 */
			ngpios = < 0xc >;                /* in zephyr/dts/x86/intel/bartlett_lake_s.dtsi:525 */
			pin-offset = < 0x19 >;           /* in zephyr/dts/x86/intel/bartlett_lake_s.dtsi:526 */
			status = "disabled";             /* in zephyr/dts/x86/intel/bartlett_lake_s.dtsi:528 */
		};

		/* node '/soc/gpio@e06a09e0' defined in zephyr/dts/x86/intel/bartlett_lake_s.dtsi:531 */
		gpio_4_f: gpio@e06a09e0 {
			compatible = "intel,gpio";       /* in zephyr/dts/x86/intel/bartlett_lake_s.dtsi:532 */
			reg = < 0xe06a09e0 0x1000 >;     /* in zephyr/dts/x86/intel/bartlett_lake_s.dtsi:533 */
			interrupts = < 0xe 0xa100 0x3 >; /* in zephyr/dts/x86/intel/bartlett_lake_s.dtsi:534 */
			interrupt-parent = < &intc >;    /* in zephyr/dts/x86/intel/bartlett_lake_s.dtsi:535 */
			group-index = < 0x3 >;           /* in zephyr/dts/x86/intel/bartlett_lake_s.dtsi:536 */
			gpio-controller;                 /* in zephyr/dts/x86/intel/bartlett_lake_s.dtsi:537 */
			#gpio-cells = < 0x2 >;           /* in zephyr/dts/x86/intel/bartlett_lake_s.dtsi:538 */
			ngpios = < 0x18 >;               /* in zephyr/dts/x86/intel/bartlett_lake_s.dtsi:539 */
			pin-offset = < 0x29 >;           /* in zephyr/dts/x86/intel/bartlett_lake_s.dtsi:540 */
			status = "disabled";             /* in zephyr/dts/x86/intel/bartlett_lake_s.dtsi:542 */
		};

		/* node '/soc/gpio@e0690700' defined in zephyr/dts/x86/intel/bartlett_lake_s.dtsi:545 */
		gpio_5_d: gpio@e0690700 {
			compatible = "intel,gpio";       /* in zephyr/dts/x86/intel/bartlett_lake_s.dtsi:546 */
			reg = < 0xe0690700 0x1000 >;     /* in zephyr/dts/x86/intel/bartlett_lake_s.dtsi:547 */
			interrupts = < 0xe 0xa100 0x3 >; /* in zephyr/dts/x86/intel/bartlett_lake_s.dtsi:548 */
			interrupt-parent = < &intc >;    /* in zephyr/dts/x86/intel/bartlett_lake_s.dtsi:549 */
			group-index = < 0x0 >;           /* in zephyr/dts/x86/intel/bartlett_lake_s.dtsi:550 */
			gpio-controller;                 /* in zephyr/dts/x86/intel/bartlett_lake_s.dtsi:551 */
			#gpio-cells = < 0x2 >;           /* in zephyr/dts/x86/intel/bartlett_lake_s.dtsi:552 */
			ngpios = < 0x18 >;               /* in zephyr/dts/x86/intel/bartlett_lake_s.dtsi:553 */
			pin-offset = < 0x0 >;            /* in zephyr/dts/x86/intel/bartlett_lake_s.dtsi:554 */
			status = "disabled";             /* in zephyr/dts/x86/intel/bartlett_lake_s.dtsi:556 */
		};

		/* node '/soc/pwm@e06a0000' defined in zephyr/dts/x86/intel/bartlett_lake_s.dtsi:559 */
		pwm0: pwm@e06a0000 {
			compatible = "intel,blinky-pwm"; /* in zephyr/dts/x86/intel/bartlett_lake_s.dtsi:560 */
			reg = < 0xe06a0000 0x400 >;      /* in zephyr/dts/x86/intel/bartlett_lake_s.dtsi:561 */
			reg-offset = < 0x304 >;          /* in zephyr/dts/x86/intel/bartlett_lake_s.dtsi:562 */
			clock-frequency = < 0x8000 >;    /* in zephyr/dts/x86/intel/bartlett_lake_s.dtsi:563 */
			max-pins = < 0x1 >;              /* in zephyr/dts/x86/intel/bartlett_lake_s.dtsi:564 */
			#pwm-cells = < 0x2 >;            /* in zephyr/dts/x86/intel/bartlett_lake_s.dtsi:565 */
			status = "disabled";             /* in zephyr/dts/x86/intel/bartlett_lake_s.dtsi:567 */
		};

		/* node '/soc/mfd@70' defined in zephyr/dts/x86/intel/bartlett_lake_s.dtsi:570 */
		mfd: mfd@70 {
			compatible = "motorola,mc146818-mfd";          /* in zephyr/dts/x86/intel/bartlett_lake_s.dtsi:571 */
			reg = < 0x70 0x1 0x71 0x1 0x72 0x1 0x73 0x1 >; /* in zephyr/dts/x86/intel/bartlett_lake_s.dtsi:572 */
			status = "okay";                               /* in zephyr/boards/intel/btl/intel_btl_s_crb.dts:35 */

			/* node '/soc/mfd@70/rtc' defined in zephyr/dts/x86/intel/bartlett_lake_s.dtsi:574 */
			rtc: counter: rtc {
				compatible = "motorola,mc146818"; /* in zephyr/dts/x86/intel/bartlett_lake_s.dtsi:575 */
				interrupts = < 0x8 0x100 0x3 >;   /* in zephyr/dts/x86/intel/bartlett_lake_s.dtsi:576 */
				interrupt-parent = < &intc >;     /* in zephyr/dts/x86/intel/bartlett_lake_s.dtsi:577 */
				alarms-count = < 0x1 >;           /* in zephyr/dts/x86/intel/bartlett_lake_s.dtsi:578 */
				status = "okay";                  /* in zephyr/boards/intel/btl/intel_btl_s_crb.dts:39 */
			};

			/* node '/soc/mfd@70/bbram' defined in zephyr/dts/x86/intel/bartlett_lake_s.dtsi:583 */
			bbram: bbram {
				compatible = "motorola,mc146818-bbram"; /* in zephyr/dts/x86/intel/bartlett_lake_s.dtsi:584 */
				size = < 0xf1 >;                        /* in zephyr/dts/x86/intel/bartlett_lake_s.dtsi:585 */
				status = "disabled";                    /* in zephyr/dts/x86/intel/bartlett_lake_s.dtsi:586 */
			};
		};

		/* node '/soc/tgpio@fe001200' defined in zephyr/dts/x86/intel/bartlett_lake_s.dtsi:592 */
		tgpio: tgpio@fe001200 {
			compatible = "intel,timeaware-gpio"; /* in zephyr/dts/x86/intel/bartlett_lake_s.dtsi:593 */
			reg = < 0xfe001200 0x100 >;          /* in zephyr/dts/x86/intel/bartlett_lake_s.dtsi:594 */
			timer-clock = < 0x124f800 >;         /* in zephyr/dts/x86/intel/bartlett_lake_s.dtsi:595 */
			max-pins = < 0x2 >;                  /* in zephyr/dts/x86/intel/bartlett_lake_s.dtsi:596 */
			status = "disabled";                 /* in zephyr/dts/x86/intel/bartlett_lake_s.dtsi:598 */
		};

		/* node '/soc/hpet@fed00000' defined in zephyr/dts/x86/intel/bartlett_lake_s.dtsi:601 */
		hpet: hpet@fed00000 {
			compatible = "intel,hpet";    /* in zephyr/dts/x86/intel/bartlett_lake_s.dtsi:602 */
			reg = < 0xfed00000 0x400 >;   /* in zephyr/dts/x86/intel/bartlett_lake_s.dtsi:603 */
			interrupts = < 0x2 0x0 0x4 >; /* in zephyr/dts/x86/intel/bartlett_lake_s.dtsi:604 */
			interrupt-parent = < &intc >; /* in zephyr/dts/x86/intel/bartlett_lake_s.dtsi:605 */
			status = "disabled";          /* in zephyr/dts/x86/intel/bartlett_lake_s.dtsi:607 */
		};

		/* node '/soc/tco_wdt@400' defined in zephyr/dts/x86/intel/bartlett_lake_s.dtsi:610 */
		tco_wdt: tco_wdt@400 {
			compatible = "intel,tco-wdt"; /* in zephyr/dts/x86/intel/bartlett_lake_s.dtsi:611 */
			reg = < 0x400 0x20 >;         /* in zephyr/dts/x86/intel/bartlett_lake_s.dtsi:612 */
			status = "disabled";          /* in zephyr/dts/x86/intel/bartlett_lake_s.dtsi:614 */
		};
	};
};
